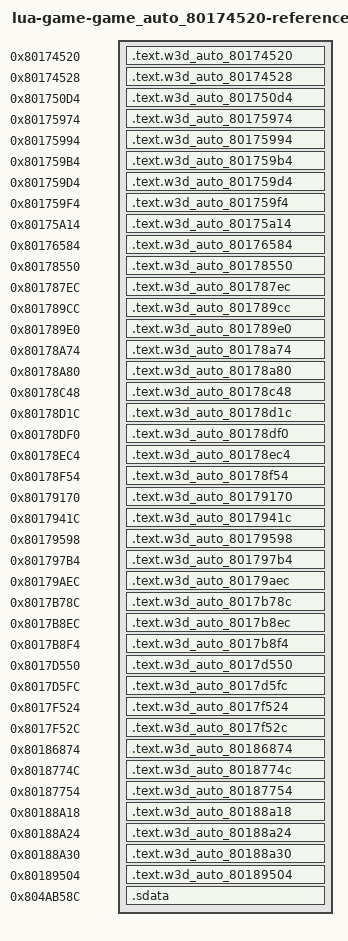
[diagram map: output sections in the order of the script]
/* Generated reference-only placements. All bodies are source-built. */
OUTPUT_FORMAT("elf32-powerpc")
OUTPUT_ARCH(powerpc)
ENTRY(w3d_auto_80174520)
_SDA_BASE_ = 0x804b2540;
_SDA2_BASE_ = 0x804c2540;
fn_80176814 = 0x80176814;
fn_801784E4 = 0x801784e4;
fn_80185AF0 = 0x80185af0;
fn_8034BF50 = 0x8034bf50;
fn_8034C148 = 0x8034c148;
fn_8034C340 = 0x8034c340;
fn_8034C538 = 0x8034c538;
fn_8034C730 = 0x8034c730;
fn_8034C928 = 0x8034c928;
SECTIONS {
  .text.w3d_auto_80174520 0x80174520 : { *(.text.w3d_auto_80174520) }
  .text.w3d_auto_80174528 0x80174528 : { *(.text.w3d_auto_80174528) }
  .text.w3d_auto_801750d4 0x801750d4 : { *(.text.w3d_auto_801750d4) }
  .text.w3d_auto_80175974 0x80175974 : { *(.text.w3d_auto_80175974) }
  .text.w3d_auto_80175994 0x80175994 : { *(.text.w3d_auto_80175994) }
  .text.w3d_auto_801759b4 0x801759b4 : { *(.text.w3d_auto_801759b4) }
  .text.w3d_auto_801759d4 0x801759d4 : { *(.text.w3d_auto_801759d4) }
  .text.w3d_auto_801759f4 0x801759f4 : { *(.text.w3d_auto_801759f4) }
  .text.w3d_auto_80175a14 0x80175a14 : { *(.text.w3d_auto_80175a14) }
  .text.w3d_auto_80176584 0x80176584 : { *(.text.w3d_auto_80176584) }
  .text.w3d_auto_80178550 0x80178550 : { *(.text.w3d_auto_80178550) }
  .text.w3d_auto_801787ec 0x801787ec : { *(.text.w3d_auto_801787ec) }
  .text.w3d_auto_801789cc 0x801789cc : { *(.text.w3d_auto_801789cc) }
  .text.w3d_auto_801789e0 0x801789e0 : { *(.text.w3d_auto_801789e0) }
  .text.w3d_auto_80178a74 0x80178a74 : { *(.text.w3d_auto_80178a74) }
  .text.w3d_auto_80178a80 0x80178a80 : { *(.text.w3d_auto_80178a80) }
  .text.w3d_auto_80178c48 0x80178c48 : { *(.text.w3d_auto_80178c48) }
  .text.w3d_auto_80178d1c 0x80178d1c : { *(.text.w3d_auto_80178d1c) }
  .text.w3d_auto_80178df0 0x80178df0 : { *(.text.w3d_auto_80178df0) }
  .text.w3d_auto_80178ec4 0x80178ec4 : { *(.text.w3d_auto_80178ec4) }
  .text.w3d_auto_80178f54 0x80178f54 : { *(.text.w3d_auto_80178f54) }
  .text.w3d_auto_80179170 0x80179170 : { *(.text.w3d_auto_80179170) }
  .text.w3d_auto_8017941c 0x8017941c : { *(.text.w3d_auto_8017941c) }
  .text.w3d_auto_80179598 0x80179598 : { *(.text.w3d_auto_80179598) }
  .text.w3d_auto_801797b4 0x801797b4 : { *(.text.w3d_auto_801797b4) }
  .text.w3d_auto_80179aec 0x80179aec : { *(.text.w3d_auto_80179aec) }
  .text.w3d_auto_8017b78c 0x8017b78c : { *(.text.w3d_auto_8017b78c) }
  .text.w3d_auto_8017b8ec 0x8017b8ec : { *(.text.w3d_auto_8017b8ec) }
  .text.w3d_auto_8017b8f4 0x8017b8f4 : { *(.text.w3d_auto_8017b8f4) }
  .text.w3d_auto_8017d550 0x8017d550 : { *(.text.w3d_auto_8017d550) }
  .text.w3d_auto_8017d5fc 0x8017d5fc : { *(.text.w3d_auto_8017d5fc) }
  .text.w3d_auto_8017f524 0x8017f524 : { *(.text.w3d_auto_8017f524) }
  .text.w3d_auto_8017f52c 0x8017f52c : { *(.text.w3d_auto_8017f52c) }
  .text.w3d_auto_80186874 0x80186874 : { *(.text.w3d_auto_80186874) }
  .text.w3d_auto_8018774c 0x8018774c : { *(.text.w3d_auto_8018774c) }
  .text.w3d_auto_80187754 0x80187754 : { *(.text.w3d_auto_80187754) }
  .text.w3d_auto_80188a18 0x80188a18 : { *(.text.w3d_auto_80188a18) }
  .text.w3d_auto_80188a24 0x80188a24 : { *(.text.w3d_auto_80188a24) }
  .text.w3d_auto_80188a30 0x80188a30 : { *(.text.w3d_auto_80188a30) }
  .text.w3d_auto_80189504 0x80189504 : { *(.text.w3d_auto_80189504) }
  .sdata 0x804ab58c (NOLOAD) : {
    . = 0x0; lbl_804AB58C = .;
    . = 0x8; lbl_804AB594 = .;
    . = 0x38; lbl_804AB5C4 = .;
    . = 0x74; lbl_804AB600 = .;
    . = 0x84; lbl_804AB610 = .;
    . = 0x90; lbl_804AB61C = .;
    . = 0xf8; lbl_804AB684 = .;
    . = 0x104; lbl_804AB690 = .;
    . = 0x4bd4; lbl_804B0160 = .;
    . += 1; }
  /DISCARD/ : { *(.text*) *(.rodata*) *(.data*) *(.bss*) *(.sdata*) *(.sbss*) *(.comment) }
}
